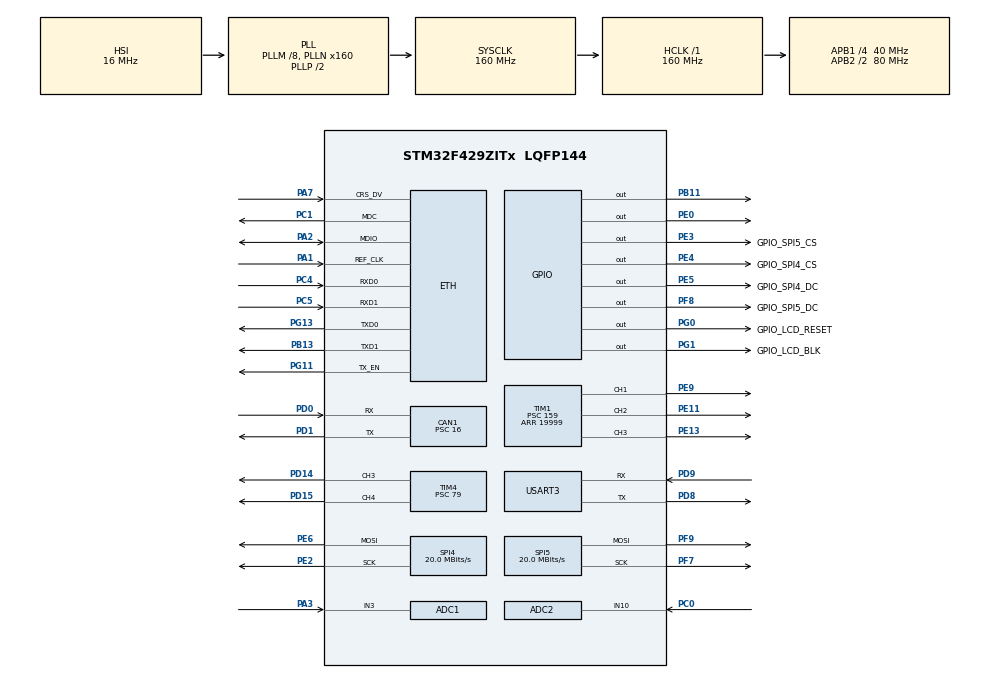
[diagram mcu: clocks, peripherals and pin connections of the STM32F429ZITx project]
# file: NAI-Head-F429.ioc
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ADC1.Channel-0\#ChannelRegularConversion=ADC_CHANNEL_3
ADC1.DMAAccessMode=ADC_DMAACCESSMODE_2
ADC1.EOCSelection=ADC_EOC_SEQ_CONV
ADC1.ExternalTrigConv=ADC_EXTERNALTRIGCONV_T2_TRGO
ADC1.Mode=ADC_DUALMODE_REGSIMULT
ADC1.NbrOfConversion=1
ADC1.NbrOfConversionFlag=1
ADC1.Rank-0\#ChannelRegularConversion=1
ADC1.SamplingTime-0\#ChannelRegularConversion=ADC_SAMPLETIME_15CYCLES
ADC1.master=1
ADC2.Channel-0\#ChannelRegularConversion=ADC_CHANNEL_10
ADC2.EOCSelection=ADC_EOC_SEQ_CONV
ADC2.Mode=ADC_DUALMODE_REGSIMULT
ADC2.NbrOfConversionFlag=1
ADC2.Rank-0\#ChannelRegularConversion=1
ADC2.SamplingTime-0\#ChannelRegularConversion=ADC_SAMPLETIME_15CYCLES
CAN1.BS1=CAN_BS1_3TQ
CAN1.BS2=CAN_BS2_1TQ
CAN1.CalculateBaudRate=500000
CAN1.CalculateTimeBit=2000
CAN1.CalculateTimeQuantum=400.0
CAN1.Mode=CAN_MODE_LOOPBACK
CAN1.Prescaler=16
Dma.ADC1.3.Direction=DMA_PERIPH_TO_MEMORY
Dma.ADC1.3.FIFOMode=DMA_FIFOMODE_DISABLE
Dma.ADC1.3.Instance=DMA2_Stream0
Dma.ADC1.3.MemDataAlignment=DMA_MDATAALIGN_HALFWORD
Dma.ADC1.3.MemInc=DMA_MINC_ENABLE
Dma.ADC1.3.Mode=DMA_NORMAL
Dma.ADC1.3.PeriphDataAlignment=DMA_PDATAALIGN_HALFWORD
Dma.ADC1.3.PeriphInc=DMA_PINC_DISABLE
Dma.ADC1.3.Priority=DMA_PRIORITY_MEDIUM
Dma.ADC2.2.Direction=DMA_PERIPH_TO_MEMORY
Dma.ADC2.2.FIFOMode=DMA_FIFOMODE_DISABLE
Dma.ADC2.2.Instance=DMA2_Stream2
Dma.ADC2.2.MemDataAlignment=DMA_MDATAALIGN_HALFWORD
Dma.ADC2.2.MemInc=DMA_MINC_ENABLE
Dma.ADC2.2.Mode=DMA_NORMAL
Dma.ADC2.2.PeriphDataAlignment=DMA_PDATAALIGN_HALFWORD
Dma.ADC2.2.PeriphInc=DMA_PINC_DISABLE
Dma.ADC2.2.Priority=DMA_PRIORITY_MEDIUM
Dma.Request0=SPI4_TX
Dma.Request1=SPI5_TX
Dma.Request2=ADC2
Dma.Request3=ADC1
Dma.SPI4_TX.0.Direction=DMA_MEMORY_TO_PERIPH
Dma.SPI4_TX.0.FIFOMode=DMA_FIFOMODE_DISABLE
Dma.SPI4_TX.0.Instance=DMA2_Stream1
Dma.SPI4_TX.0.MemDataAlignment=DMA_MDATAALIGN_HALFWORD
Dma.SPI4_TX.0.MemInc=DMA_MINC_ENABLE
Dma.SPI4_TX.0.Mode=DMA_NORMAL
Dma.SPI4_TX.0.PeriphDataAlignment=DMA_PDATAALIGN_HALFWORD
Dma.SPI4_TX.0.PeriphInc=DMA_PINC_DISABLE
Dma.SPI4_TX.0.Priority=DMA_PRIORITY_LOW
Dma.SPI5_TX.1.Direction=DMA_MEMORY_TO_PERIPH
Dma.SPI5_TX.1.FIFOMode=DMA_FIFOMODE_DISABLE
Dma.SPI5_TX.1.Instance=DMA2_Stream4
Dma.SPI5_TX.1.MemDataAlignment=DMA_MDATAALIGN_HALFWORD
Dma.SPI5_TX.1.MemInc=DMA_MINC_ENABLE
Dma.SPI5_TX.1.Mode=DMA_NORMAL
Dma.SPI5_TX.1.PeriphDataAlignment=DMA_PDATAALIGN_HALFWORD
Dma.SPI5_TX.1.PeriphInc=DMA_PINC_DISABLE
Dma.SPI5_TX.1.Priority=DMA_PRIORITY_LOW
ETH.MACAddr=00\:80\:E1\:01\:00\:00
ETH.MediaInterface=HAL_ETH_RMII_MODE
LWIP.BSP.number=1
LWIP.GATEWAY_ADDRESS=172.028.000.001
LWIP.IP_ADDRESS=172.028.000.064
LWIP.LWIP_DHCP=0
LWIP.LWIP_IGMP=1
LWIP.LWIP_MULTICAST_TX_OPTIONS=1
LWIP.LWIP_NETIF_EXT_STATUS_CALLBACK=0
LWIP.NETMASK_ADDRESS=255.255.255.000
LWIP.Version=v2.1.2_Cube
LWIP0.BSP.STBoard=false
LWIP0.BSP.api=BSP_COMPONENT_DRIVER
LWIP0.BSP.component=LAN8742
LWIP0.BSP.instance=LAN8742
LWIP0.BSP.name=Driver_PHY
LWIP0.BSP.semaphore=S_LAN8742
LWIP0.BSP.solution=LAN8742
Mcu.Family=STM32F4
Mcu.Name=STM32F429ZITx
Mcu.Package=LQFP144
NVIC.DMA2_Stream0_IRQn=true\:0\:0\:false\:false\:true\:false\:true\:true
NVIC.DMA2_Stream1_IRQn=true\:0\:0\:false\:false\:true\:false\:true\:true
NVIC.DMA2_Stream2_IRQn=true\:0\:0\:false\:false\:true\:false\:true\:true
NVIC.DMA2_Stream4_IRQn=true\:0\:0\:false\:false\:true\:false\:true\:true
NVIC.PriorityGroup=NVIC_PRIORITYGROUP_2
NVIC.TIM6_DAC_IRQn=true\:1\:1\:true\:false\:true\:true\:true\:true
NVIC.TIM7_IRQn=true\:1\:2\:true\:false\:true\:true\:true\:true
PA1.Mode=RMII
PA1.Signal=ETH_REF_CLK
PA13.Mode=Serial_Wire
PA13.Signal=SYS_JTMS-SWDIO
PA14.Mode=Serial_Wire
PA14.Signal=SYS_JTCK-SWCLK
PA2.Mode=RMII
PA2.Signal=ETH_MDIO
PA3.Signal=ADCx_IN3
PA7.Mode=RMII
PA7.Signal=ETH_CRS_DV
PB11.Signal=GPIO_Output
PB13.Mode=RMII
PB13.Signal=ETH_TXD1
PC0.Signal=ADCx_IN10
PC1.Mode=RMII
PC1.Signal=ETH_MDC
PC4.Mode=RMII
PC4.Signal=ETH_RXD0
PC5.Mode=RMII
PC5.Signal=ETH_RXD1
PD0.GPIO_PuPd=GPIO_PULLUP
PD0.Mode=CAN_Activate
PD0.Signal=CAN1_RX
PD1.Mode=CAN_Activate
PD1.Signal=CAN1_TX
PD14.Signal=S_TIM4_CH3
PD15.Signal=S_TIM4_CH4
PD8.Mode=Asynchronous
PD8.Signal=USART3_TX
PD9.Mode=Asynchronous
PD9.Signal=USART3_RX
PE0.Signal=GPIO_Output
PE11.Signal=S_TIM1_CH2
PE13.Signal=S_TIM1_CH3
PE2.Mode=TX_Only_Simplex_Unidirect_Master
PE2.Signal=SPI4_SCK
PE3.GPIO_Label=GPIO_SPI5_CS
PE3.PinState=GPIO_PIN_SET
PE3.Signal=GPIO_Output
PE4.GPIO_Label=GPIO_SPI4_CS
PE4.PinState=GPIO_PIN_SET
PE4.Signal=GPIO_Output
PE5.GPIO_Label=GPIO_SPI4_DC
PE5.PinState=GPIO_PIN_SET
PE5.Signal=GPIO_Output
PE6.Mode=TX_Only_Simplex_Unidirect_Master
PE6.Signal=SPI4_MOSI
PE9.Signal=S_TIM1_CH1
PF7.Mode=TX_Only_Simplex_Unidirect_Master
PF7.Signal=SPI5_SCK
PF8.GPIO_Label=GPIO_SPI5_DC
PF8.PinState=GPIO_PIN_SET
PF8.Signal=GPIO_Output
PF9.Mode=TX_Only_Simplex_Unidirect_Master
PF9.Signal=SPI5_MOSI
PG0.GPIO_Label=GPIO_LCD_RESET
PG0.Signal=GPIO_Output
PG1.GPIO_Label=GPIO_LCD_BLK
PG1.Signal=GPIO_Output
PG11.Mode=RMII
PG11.Signal=ETH_TX_EN
PG13.Mode=RMII
PG13.Signal=ETH_TXD0
PH0/OSC_IN.Mode=HSE-External-Oscillator
PH0/OSC_IN.Signal=RCC_OSC_IN
PH1/OSC_OUT.Mode=HSE-External-Oscillator
PH1/OSC_OUT.Signal=RCC_OSC_OUT
ProjectManager.HeapSize=0x200
ProjectManager.StackSize=0x400
ProjectManager.TargetToolchain=STM32CubeIDE
RCC.48MHZClocksFreq_Value=80000000
RCC.AHBFreq_Value=160000000
RCC.APB1CLKDivider=RCC_HCLK_DIV4
RCC.APB1Freq_Value=40000000
RCC.APB1TimFreq_Value=80000000
RCC.APB2CLKDivider=RCC_HCLK_DIV2
RCC.APB2Freq_Value=80000000
RCC.APB2TimFreq_Value=160000000
RCC.CortexFreq_Value=160000000
RCC.HCLKFreq_Value=160000000
RCC.HSE_VALUE=25000000
RCC.HSI_VALUE=16000000
RCC.LSE_VALUE=32768
RCC.PLLM=8
RCC.PLLN=160
RCC.SYSCLKFreq_VALUE=160000000
RCC.SYSCLKSource=RCC_SYSCLKSOURCE_PLLCLK
RCC.VCOOutputFreq_Value=320000000
SH.ADCx_IN10.0=ADC2_IN10,IN10
SH.ADCx_IN3.0=ADC1_IN3,IN3
SH.S_TIM1_CH1.0=TIM1_CH1,PWM Generation1 CH1
SH.S_TIM1_CH2.0=TIM1_CH2,PWM Generation2 CH2
SH.S_TIM1_CH3.0=TIM1_CH3,PWM Generation3 CH3
SH.S_TIM4_CH3.0=TIM4_CH3,PWM Generation3 CH3
SH.S_TIM4_CH4.0=TIM4_CH4,PWM Generation4 CH4
SPI4.BaudRatePrescaler=SPI_BAUDRATEPRESCALER_4
SPI4.CalculateBaudRate=20.0 MBits/s
SPI4.Direction=SPI_DIRECTION_2LINES
SPI4.Mode=SPI_MODE_MASTER
SPI4.VirtualType=VM_MASTER
SPI5.BaudRatePrescaler=SPI_BAUDRATEPRESCALER_4
SPI5.CalculateBaudRate=20.0 MBits/s
SPI5.Direction=SPI_DIRECTION_2LINES
SPI5.Mode=SPI_MODE_MASTER
SPI5.VirtualType=VM_MASTER
TIM1.Channel-PWM\ Generation1\ CH1=TIM_CHANNEL_1
TIM1.Channel-PWM\ Generation2\ CH2=TIM_CHANNEL_2
TIM1.Channel-PWM\ Generation3\ CH3=TIM_CHANNEL_3
TIM1.Period=19999
TIM1.Prescaler=159
TIM1.Pulse-PWM\ Generation1\ CH1=1500
TIM1.Pulse-PWM\ Generation2\ CH2=1500
TIM1.Pulse-PWM\ Generation3\ CH3=1500
TIM2.Period=39
TIM2.Prescaler=79
TIM2.TIM_MasterOutputTrigger=TIM_TRGO_UPDATE
TIM4.Channel-PWM\ Generation3\ CH3=TIM_CHANNEL_3
TIM4.Channel-PWM\ Generation4\ CH4=TIM_CHANNEL_4
TIM4.Period=19999 
TIM4.Prescaler=79
TIM4.Pulse-PWM\ Generation3\ CH3=1500
TIM4.Pulse-PWM\ Generation4\ CH4=1500
TIM6.Period=4999
TIM6.Prescaler=799
TIM7.Period=9999
TIM7.Prescaler=79
USART3.VirtualMode=VM_ASYNC
VP_LWIP_VS_Enabled.Mode=Enabled
VP_TIM2_VS_ClockSourceINT.Mode=Internal
VP_TIM6_VS_ClockSourceINT.Mode=Enable_Timer
VP_TIM7_VS_ClockSourceINT.Mode=Enable_Timer
board=custom

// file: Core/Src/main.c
/* USER CODE BEGIN Header */
/**
  ******************************************************************************
  * @file           : main.c
  * @brief          : Main program body
  ******************************************************************************
  * @attention
  *
  * Copyright (c) 2024 STMicroelectronics.
  * All rights reserved.
  *
  * This software is licensed under terms that can be found in the LICENSE file
  * in the root directory of this software component.
  * If no LICENSE file comes with this software, it is provided AS-IS.
  *
  ******************************************************************************
  */
/* USER CODE END Header */
#include "main.h"
#include "lwip.h"

ADC_HandleTypeDef hadc1;
ADC_HandleTypeDef hadc2;
DMA_HandleTypeDef hdma_adc1;
DMA_HandleTypeDef hdma_adc2;

CAN_HandleTypeDef hcan1;

SPI_HandleTypeDef hspi4;
SPI_HandleTypeDef hspi5;
DMA_HandleTypeDef hdma_spi4_tx;
DMA_HandleTypeDef hdma_spi5_tx;

TIM_HandleTypeDef htim1;
TIM_HandleTypeDef htim2;
TIM_HandleTypeDef htim4;
TIM_HandleTypeDef htim6;
TIM_HandleTypeDef htim7;

UART_HandleTypeDef huart3;

void SystemClock_Config(void);
static void MX_GPIO_Init(void);
static void MX_DMA_Init(void);
static void MX_USART3_UART_Init(void);
static void MX_TIM1_Init(void);
static void MX_TIM4_Init(void);
static void MX_SPI4_Init(void);
static void MX_SPI5_Init(void);
static void MX_CAN1_Init(void);
static void MX_ADC1_Init(void);
static void MX_ADC2_Init(void);
static void MX_TIM6_Init(void);
static void MX_TIM7_Init(void);
static void MX_TIM2_Init(void);

int main(void)
{

  /* MCU Configuration--------------------------------------------------------*/

  /* Reset of all peripherals, Initializes the Flash interface and the Systick. */
  HAL_Init();

  /* Configure the system clock */
  SystemClock_Config();

  /* USER CODE BEGIN SysInit */
  // 2 seconds to wait for Ethernet PHY to wake up
  HAL_Delay(2000);
  /* USER CODE END SysInit */

  /* Initialize all configured peripherals */
  MX_GPIO_Init();
  MX_DMA_Init();
  MX_LWIP_Init();
  MX_USART3_UART_Init();
  MX_TIM1_Init();
  MX_TIM4_Init();
  MX_SPI4_Init();
  MX_SPI5_Init();
  MX_CAN1_Init();
  MX_ADC1_Init();
  MX_ADC2_Init();
  MX_TIM6_Init();
  MX_TIM7_Init();
  MX_TIM2_Init();
  /* USER CODE BEGIN 2 */
  APP_init();
  /* USER CODE END 2 */

  /* Infinite loop */
  /* USER CODE BEGIN WHILE */
  while (1)
  {
    APP_main();
    /* USER CODE END WHILE */

  }
}

void SystemClock_Config(void)
{
  RCC_OscInitTypeDef RCC_OscInitStruct = {0};
  RCC_ClkInitTypeDef RCC_ClkInitStruct = {0};

  /** Configure the main internal regulator output voltage
  */
  __HAL_RCC_PWR_CLK_ENABLE();
  __HAL_PWR_VOLTAGESCALING_CONFIG(PWR_REGULATOR_VOLTAGE_SCALE1);

  /** Initializes the RCC Oscillators according to the specified parameters
  * in the RCC_OscInitTypeDef structure.
  */
  RCC_OscInitStruct.OscillatorType = RCC_OSCILLATORTYPE_HSI;
  RCC_OscInitStruct.HSIState = RCC_HSI_ON;
  RCC_OscInitStruct.HSICalibrationValue = RCC_HSICALIBRATION_DEFAULT;
  RCC_OscInitStruct.PLL.PLLState = RCC_PLL_ON;
  RCC_OscInitStruct.PLL.PLLSource = RCC_PLLSOURCE_HSI;
  RCC_OscInitStruct.PLL.PLLM = 8;
  RCC_OscInitStruct.PLL.PLLN = 160;
  RCC_OscInitStruct.PLL.PLLP = RCC_PLLP_DIV2;
  RCC_OscInitStruct.PLL.PLLQ = 4;
  if (HAL_RCC_OscConfig(&RCC_OscInitStruct) != HAL_OK)
  {
    Error_Handler();
  }

  /** Initializes the CPU, AHB and APB buses clocks
  */
  RCC_ClkInitStruct.ClockType = RCC_CLOCKTYPE_HCLK|RCC_CLOCKTYPE_SYSCLK
                              |RCC_CLOCKTYPE_PCLK1|RCC_CLOCKTYPE_PCLK2;
  RCC_ClkInitStruct.SYSCLKSource = RCC_SYSCLKSOURCE_PLLCLK;
  RCC_ClkInitStruct.AHBCLKDivider = RCC_SYSCLK_DIV1;
  RCC_ClkInitStruct.APB1CLKDivider = RCC_HCLK_DIV4;
  RCC_ClkInitStruct.APB2CLKDivider = RCC_HCLK_DIV2;

  if (HAL_RCC_ClockConfig(&RCC_ClkInitStruct, FLASH_LATENCY_5) != HAL_OK)
  {
    Error_Handler();
  }
}

static void MX_ADC1_Init(void)
{

  ADC_MultiModeTypeDef multimode = {0};
  ADC_ChannelConfTypeDef sConfig = {0};

  /** Configure the global features of the ADC (Clock, Resolution, Data Alignment and number of conversion)
  */
  hadc1.Instance = ADC1;
  hadc1.Init.ClockPrescaler = ADC_CLOCK_SYNC_PCLK_DIV4;
  hadc1.Init.Resolution = ADC_RESOLUTION_12B;
  hadc1.Init.ScanConvMode = DISABLE;
  hadc1.Init.ContinuousConvMode = DISABLE;
  hadc1.Init.DiscontinuousConvMode = DISABLE;
  hadc1.Init.ExternalTrigConvEdge = ADC_EXTERNALTRIGCONVEDGE_RISING;
  hadc1.Init.ExternalTrigConv = ADC_EXTERNALTRIGCONV_T2_TRGO;
  hadc1.Init.DataAlign = ADC_DATAALIGN_RIGHT;
  hadc1.Init.NbrOfConversion = 1;
  hadc1.Init.DMAContinuousRequests = DISABLE;
  hadc1.Init.EOCSelection = ADC_EOC_SEQ_CONV;
  if (HAL_ADC_Init(&hadc1) != HAL_OK)
  {
    Error_Handler();
  }

  /** Configure the ADC multi-mode
  */
  multimode.Mode = ADC_DUALMODE_REGSIMULT;
  multimode.DMAAccessMode = ADC_DMAACCESSMODE_2;
  multimode.TwoSamplingDelay = ADC_TWOSAMPLINGDELAY_5CYCLES;
  if (HAL_ADCEx_MultiModeConfigChannel(&hadc1, &multimode) != HAL_OK)
  {
    Error_Handler();
  }

  /** Configure for the selected ADC regular channel its corresponding rank in the sequencer and its sample time.
  */
  sConfig.Channel = ADC_CHANNEL_3;
  sConfig.Rank = 1;
  sConfig.SamplingTime = ADC_SAMPLETIME_15CYCLES;
  if (HAL_ADC_ConfigChannel(&hadc1, &sConfig) != HAL_OK)
  {
    Error_Handler();
  }

}

static void MX_ADC2_Init(void)
{

  ADC_ChannelConfTypeDef sConfig = {0};

  /** Configure the global features of the ADC (Clock, Resolution, Data Alignment and number of conversion)
  */
  hadc2.Instance = ADC2;
  hadc2.Init.ClockPrescaler = ADC_CLOCK_SYNC_PCLK_DIV4;
  hadc2.Init.Resolution = ADC_RESOLUTION_12B;
  hadc2.Init.ScanConvMode = DISABLE;
  hadc2.Init.ContinuousConvMode = DISABLE;
  hadc2.Init.DiscontinuousConvMode = DISABLE;
  hadc2.Init.DataAlign = ADC_DATAALIGN_RIGHT;
  hadc2.Init.NbrOfConversion = 1;
  hadc2.Init.DMAContinuousRequests = DISABLE;
  hadc2.Init.EOCSelection = ADC_EOC_SEQ_CONV;
  if (HAL_ADC_Init(&hadc2) != HAL_OK)
  {
    Error_Handler();
  }

  /** Configure for the selected ADC regular channel its corresponding rank in the sequencer and its sample time.
  */
  sConfig.Channel = ADC_CHANNEL_10;
  sConfig.Rank = 1;
  sConfig.SamplingTime = ADC_SAMPLETIME_15CYCLES;
  if (HAL_ADC_ConfigChannel(&hadc2, &sConfig) != HAL_OK)
  {
    Error_Handler();
  }

}

static void MX_CAN1_Init(void)
{

  hcan1.Instance = CAN1;
  hcan1.Init.Prescaler = 16;
  hcan1.Init.Mode = CAN_MODE_LOOPBACK;
  hcan1.Init.SyncJumpWidth = CAN_SJW_1TQ;
  hcan1.Init.TimeSeg1 = CAN_BS1_3TQ;
  hcan1.Init.TimeSeg2 = CAN_BS2_1TQ;
  hcan1.Init.TimeTriggeredMode = DISABLE;
  hcan1.Init.AutoBusOff = DISABLE;
  hcan1.Init.AutoWakeUp = DISABLE;
  hcan1.Init.AutoRetransmission = DISABLE;
  hcan1.Init.ReceiveFifoLocked = DISABLE;
  hcan1.Init.TransmitFifoPriority = DISABLE;
  if (HAL_CAN_Init(&hcan1) != HAL_OK)
  {
    Error_Handler();
  }

}

static void MX_SPI4_Init(void)
{

  /* SPI4 parameter configuration*/
  hspi4.Instance = SPI4;
  hspi4.Init.Mode = SPI_MODE_MASTER;
  hspi4.Init.Direction = SPI_DIRECTION_2LINES;
  hspi4.Init.DataSize = SPI_DATASIZE_8BIT;
  hspi4.Init.CLKPolarity = SPI_POLARITY_LOW;
  hspi4.Init.CLKPhase = SPI_PHASE_1EDGE;
  hspi4.Init.NSS = SPI_NSS_SOFT;
  hspi4.Init.BaudRatePrescaler = SPI_BAUDRATEPRESCALER_4;
  hspi4.Init.FirstBit = SPI_FIRSTBIT_MSB;
  hspi4.Init.TIMode = SPI_TIMODE_DISABLE;
  hspi4.Init.CRCCalculation = SPI_CRCCALCULATION_DISABLE;
  hspi4.Init.CRCPolynomial = 10;
  if (HAL_SPI_Init(&hspi4) != HAL_OK)
  {
    Error_Handler();
  }

}

static void MX_SPI5_Init(void)
{

  /* SPI5 parameter configuration*/
  hspi5.Instance = SPI5;
  hspi5.Init.Mode = SPI_MODE_MASTER;
  hspi5.Init.Direction = SPI_DIRECTION_2LINES;
  hspi5.Init.DataSize = SPI_DATASIZE_8BIT;
  hspi5.Init.CLKPolarity = SPI_POLARITY_LOW;
  hspi5.Init.CLKPhase = SPI_PHASE_1EDGE;
  hspi5.Init.NSS = SPI_NSS_SOFT;
  hspi5.Init.BaudRatePrescaler = SPI_BAUDRATEPRESCALER_4;
  hspi5.Init.FirstBit = SPI_FIRSTBIT_MSB;
  hspi5.Init.TIMode = SPI_TIMODE_DISABLE;
  hspi5.Init.CRCCalculation = SPI_CRCCALCULATION_DISABLE;
  hspi5.Init.CRCPolynomial = 10;
  if (HAL_SPI_Init(&hspi5) != HAL_OK)
  {
    Error_Handler();
  }

}

static void MX_TIM1_Init(void)
{

  TIM_MasterConfigTypeDef sMasterConfig = {0};
  TIM_OC_InitTypeDef sConfigOC = {0};
  TIM_BreakDeadTimeConfigTypeDef sBreakDeadTimeConfig = {0};

  htim1.Instance = TIM1;
  htim1.Init.Prescaler = 159;
  htim1.Init.CounterMode = TIM_COUNTERMODE_UP;
  htim1.Init.Period = 19999;
  htim1.Init.ClockDivision = TIM_CLOCKDIVISION_DIV1;
  htim1.Init.RepetitionCounter = 0;
  htim1.Init.AutoReloadPreload = TIM_AUTORELOAD_PRELOAD_DISABLE;
  if (HAL_TIM_PWM_Init(&htim1) != HAL_OK)
  {
    Error_Handler();
  }
  sMasterConfig.MasterOutputTrigger = TIM_TRGO_RESET;
  sMasterConfig.MasterSlaveMode = TIM_MASTERSLAVEMODE_DISABLE;
  if (HAL_TIMEx_MasterConfigSynchronization(&htim1, &sMasterConfig) != HAL_OK)
  {
    Error_Handler();
  }
  sConfigOC.OCMode = TIM_OCMODE_PWM1;
  sConfigOC.Pulse = 1500;
  sConfigOC.OCPolarity = TIM_OCPOLARITY_HIGH;
  sConfigOC.OCNPolarity = TIM_OCNPOLARITY_HIGH;
  sConfigOC.OCFastMode = TIM_OCFAST_DISABLE;
  sConfigOC.OCIdleState = TIM_OCIDLESTATE_RESET;
  sConfigOC.OCNIdleState = TIM_OCNIDLESTATE_RESET;
  if (HAL_TIM_PWM_ConfigChannel(&htim1, &sConfigOC, TIM_CHANNEL_1) != HAL_OK)
  {
    Error_Handler();
  }
  if (HAL_TIM_PWM_ConfigChannel(&htim1, &sConfigOC, TIM_CHANNEL_2) != HAL_OK)
  {
    Error_Handler();
  }
  if (HAL_TIM_PWM_ConfigChannel(&htim1, &sConfigOC, TIM_CHANNEL_3) != HAL_OK)
  {
    Error_Handler();
  }
  sBreakDeadTimeConfig.OffStateRunMode = TIM_OSSR_DISABLE;
  sBreakDeadTimeConfig.OffStateIDLEMode = TIM_OSSI_DISABLE;
  sBreakDeadTimeConfig.LockLevel = TIM_LOCKLEVEL_OFF;
  sBreakDeadTimeConfig.DeadTime = 0;
  sBreakDeadTimeConfig.BreakState = TIM_BREAK_DISABLE;
  sBreakDeadTimeConfig.BreakPolarity = TIM_BREAKPOLARITY_HIGH;
  sBreakDeadTimeConfig.AutomaticOutput = TIM_AUTOMATICOUTPUT_DISABLE;
  if (HAL_TIMEx_ConfigBreakDeadTime(&htim1, &sBreakDeadTimeConfig) != HAL_OK)
  {
    Error_Handler();
  }
  HAL_TIM_MspPostInit(&htim1);

}

static void MX_TIM2_Init(void)
{

  TIM_ClockConfigTypeDef sClockSourceConfig = {0};
  TIM_MasterConfigTypeDef sMasterConfig = {0};

  htim2.Instance = TIM2;
  htim2.Init.Prescaler = 79;
  htim2.Init.CounterMode = TIM_COUNTERMODE_UP;
  htim2.Init.Period = 39;
  htim2.Init.ClockDivision = TIM_CLOCKDIVISION_DIV1;
  htim2.Init.AutoReloadPreload = TIM_AUTORELOAD_PRELOAD_DISABLE;
  if (HAL_TIM_Base_Init(&htim2) != HAL_OK)
  {
    Error_Handler();
  }
  sClockSourceConfig.ClockSource = TIM_CLOCKSOURCE_INTERNAL;
  if (HAL_TIM_ConfigClockSource(&htim2, &sClockSourceConfig) != HAL_OK)
  {
    Error_Handler();
  }
  sMasterConfig.MasterOutputTrigger = TIM_TRGO_UPDATE;
  sMasterConfig.MasterSlaveMode = TIM_MASTERSLAVEMODE_DISABLE;
  if (HAL_TIMEx_MasterConfigSynchronization(&htim2, &sMasterConfig) != HAL_OK)
  {
    Error_Handler();
  }

}

static void MX_TIM4_Init(void)
{

  TIM_MasterConfigTypeDef sMasterConfig = {0};
  TIM_OC_InitTypeDef sConfigOC = {0};

  htim4.Instance = TIM4;
  htim4.Init.Prescaler = 79;
  htim4.Init.CounterMode = TIM_COUNTERMODE_UP;
  htim4.Init.Period = 19999 ;
  htim4.Init.ClockDivision = TIM_CLOCKDIVISION_DIV1;
  htim4.Init.AutoReloadPreload = TIM_AUTORELOAD_PRELOAD_DISABLE;
  if (HAL_TIM_PWM_Init(&htim4) != HAL_OK)
  {
    Error_Handler();
  }
  sMasterConfig.MasterOutputTrigger = TIM_TRGO_RESET;
  sMasterConfig.MasterSlaveMode = TIM_MASTERSLAVEMODE_DISABLE;
  if (HAL_TIMEx_MasterConfigSynchronization(&htim4, &sMasterConfig) != HAL_OK)
  {
    Error_Handler();
  }
  sConfigOC.OCMode = TIM_OCMODE_PWM1;
  sConfigOC.Pulse = 1500;
  sConfigOC.OCPolarity = TIM_OCPOLARITY_HIGH;
  sConfigOC.OCFastMode = TIM_OCFAST_DISABLE;
  if (HAL_TIM_PWM_ConfigChannel(&htim4, &sConfigOC, TIM_CHANNEL_3) != HAL_OK)
  {
    Error_Handler();
  }
  if (HAL_TIM_PWM_ConfigChannel(&htim4, &sConfigOC, TIM_CHANNEL_4) != HAL_OK)
  {
    Error_Handler();
  }
  HAL_TIM_MspPostInit(&htim4);

}

static void MX_TIM6_Init(void)
{

  TIM_MasterConfigTypeDef sMasterConfig = {0};

  htim6.Instance = TIM6;
  htim6.Init.Prescaler = 799;
  htim6.Init.CounterMode = TIM_COUNTERMODE_UP;
  htim6.Init.Period = 4999;
  htim6.Init.AutoReloadPreload = TIM_AUTORELOAD_PRELOAD_DISABLE;
  if (HAL_TIM_Base_Init(&htim6) != HAL_OK)
  {
    Error_Handler();
  }
  sMasterConfig.MasterOutputTrigger = TIM_TRGO_RESET;
  sMasterConfig.MasterSlaveMode = TIM_MASTERSLAVEMODE_DISABLE;
  if (HAL_TIMEx_MasterConfigSynchronization(&htim6, &sMasterConfig) != HAL_OK)
  {
    Error_Handler();
  }

}

static void MX_TIM7_Init(void)
{

  TIM_MasterConfigTypeDef sMasterConfig = {0};

  htim7.Instance = TIM7;
  htim7.Init.Prescaler = 79;
  htim7.Init.CounterMode = TIM_COUNTERMODE_UP;
  htim7.Init.Period = 9999;
  htim7.Init.AutoReloadPreload = TIM_AUTORELOAD_PRELOAD_DISABLE;
  if (HAL_TIM_Base_Init(&htim7) != HAL_OK)
  {
    Error_Handler();
  }
  sMasterConfig.MasterOutputTrigger = TIM_TRGO_RESET;
  sMasterConfig.MasterSlaveMode = TIM_MASTERSLAVEMODE_DISABLE;
  if (HAL_TIMEx_MasterConfigSynchronization(&htim7, &sMasterConfig) != HAL_OK)
  {
    Error_Handler();
  }

}

static void MX_USART3_UART_Init(void)
{

  huart3.Instance = USART3;
  huart3.Init.BaudRate = 115200;
  huart3.Init.WordLength = UART_WORDLENGTH_8B;
  huart3.Init.StopBits = UART_STOPBITS_1;
  huart3.Init.Parity = UART_PARITY_NONE;
  huart3.Init.Mode = UART_MODE_TX_RX;
  huart3.Init.HwFlowCtl = UART_HWCONTROL_NONE;
  huart3.Init.OverSampling = UART_OVERSAMPLING_16;
  if (HAL_UART_Init(&huart3) != HAL_OK)
  {
    Error_Handler();
  }

}

static void MX_DMA_Init(void)
{

  /* DMA controller clock enable */
  __HAL_RCC_DMA2_CLK_ENABLE();

  /* DMA interrupt init */
  /* DMA2_Stream0_IRQn interrupt configuration */
  HAL_NVIC_SetPriority(DMA2_Stream0_IRQn, 0, 0);
  HAL_NVIC_EnableIRQ(DMA2_Stream0_IRQn);
  /* DMA2_Stream1_IRQn interrupt configuration */
  HAL_NVIC_SetPriority(DMA2_Stream1_IRQn, 0, 0);
  HAL_NVIC_EnableIRQ(DMA2_Stream1_IRQn);
  /* DMA2_Stream2_IRQn interrupt configuration */
  HAL_NVIC_SetPriority(DMA2_Stream2_IRQn, 0, 0);
  HAL_NVIC_EnableIRQ(DMA2_Stream2_IRQn);
  /* DMA2_Stream4_IRQn interrupt configuration */
  HAL_NVIC_SetPriority(DMA2_Stream4_IRQn, 0, 0);
  HAL_NVIC_EnableIRQ(DMA2_Stream4_IRQn);

}

static void MX_GPIO_Init(void)
{
  GPIO_InitTypeDef GPIO_InitStruct = {0};

  /* GPIO Ports Clock Enable */
  __HAL_RCC_GPIOE_CLK_ENABLE();
  __HAL_RCC_GPIOF_CLK_ENABLE();
  __HAL_RCC_GPIOH_CLK_ENABLE();
  __HAL_RCC_GPIOC_CLK_ENABLE();
  __HAL_RCC_GPIOA_CLK_ENABLE();
  __HAL_RCC_GPIOG_CLK_ENABLE();
  __HAL_RCC_GPIOB_CLK_ENABLE();
  __HAL_RCC_GPIOD_CLK_ENABLE();

  /*Configure GPIO pin Output Level */
  HAL_GPIO_WritePin(GPIOE, GPIO_SPI5_CS_Pin|GPIO_SPI4_CS_Pin|GPIO_SPI4_DC_Pin, GPIO_PIN_SET);

  /*Configure GPIO pin Output Level */
  HAL_GPIO_WritePin(GPIO_SPI5_DC_GPIO_Port, GPIO_SPI5_DC_Pin, GPIO_PIN_SET);

  /*Configure GPIO pin Output Level */
  HAL_GPIO_WritePin(GPIOG, GPIO_LCD_RESET_Pin|GPIO_LCD_BLK_Pin, GPIO_PIN_RESET);

  /*Configure GPIO pin Output Level */
  HAL_GPIO_WritePin(GPIOB, GPIO_PIN_11, GPIO_PIN_RESET);

  /*Configure GPIO pin Output Level */
  HAL_GPIO_WritePin(GPIOE, GPIO_PIN_0, GPIO_PIN_RESET);

  /*Configure GPIO pins : GPIO_SPI5_CS_Pin GPIO_SPI4_CS_Pin GPIO_SPI4_DC_Pin PE0 */
  GPIO_InitStruct.Pin = GPIO_SPI5_CS_Pin|GPIO_SPI4_CS_Pin|GPIO_SPI4_DC_Pin|GPIO_PIN_0;
  GPIO_InitStruct.Mode = GPIO_MODE_OUTPUT_PP;
  GPIO_InitStruct.Pull = GPIO_NOPULL;
  GPIO_InitStruct.Speed = GPIO_SPEED_FREQ_LOW;
  HAL_GPIO_Init(GPIOE, &GPIO_InitStruct);

  /*Configure GPIO pin : GPIO_SPI5_DC_Pin */
  GPIO_InitStruct.Pin = GPIO_SPI5_DC_Pin;
  GPIO_InitStruct.Mode = GPIO_MODE_OUTPUT_PP;
  GPIO_InitStruct.Pull = GPIO_NOPULL;
  GPIO_InitStruct.Speed = GPIO_SPEED_FREQ_LOW;
  HAL_GPIO_Init(GPIO_SPI5_DC_GPIO_Port, &GPIO_InitStruct);

  /*Configure GPIO pins : GPIO_LCD_RESET_Pin GPIO_LCD_BLK_Pin */
  GPIO_InitStruct.Pin = GPIO_LCD_RESET_Pin|GPIO_LCD_BLK_Pin;
  GPIO_InitStruct.Mode = GPIO_MODE_OUTPUT_PP;
  GPIO_InitStruct.Pull = GPIO_NOPULL;
  GPIO_InitStruct.Speed = GPIO_SPEED_FREQ_LOW;
  HAL_GPIO_Init(GPIOG, &GPIO_InitStruct);

  /*Configure GPIO pin : PB11 */
  GPIO_InitStruct.Pin = GPIO_PIN_11;
  GPIO_InitStruct.Mode = GPIO_MODE_OUTPUT_PP;
  GPIO_InitStruct.Pull = GPIO_NOPULL;
  GPIO_InitStruct.Speed = GPIO_SPEED_FREQ_LOW;
  HAL_GPIO_Init(GPIOB, &GPIO_InitStruct);

}

void Error_Handler(void)
{
  __disable_irq();
  while (1)
  {
  }
}
